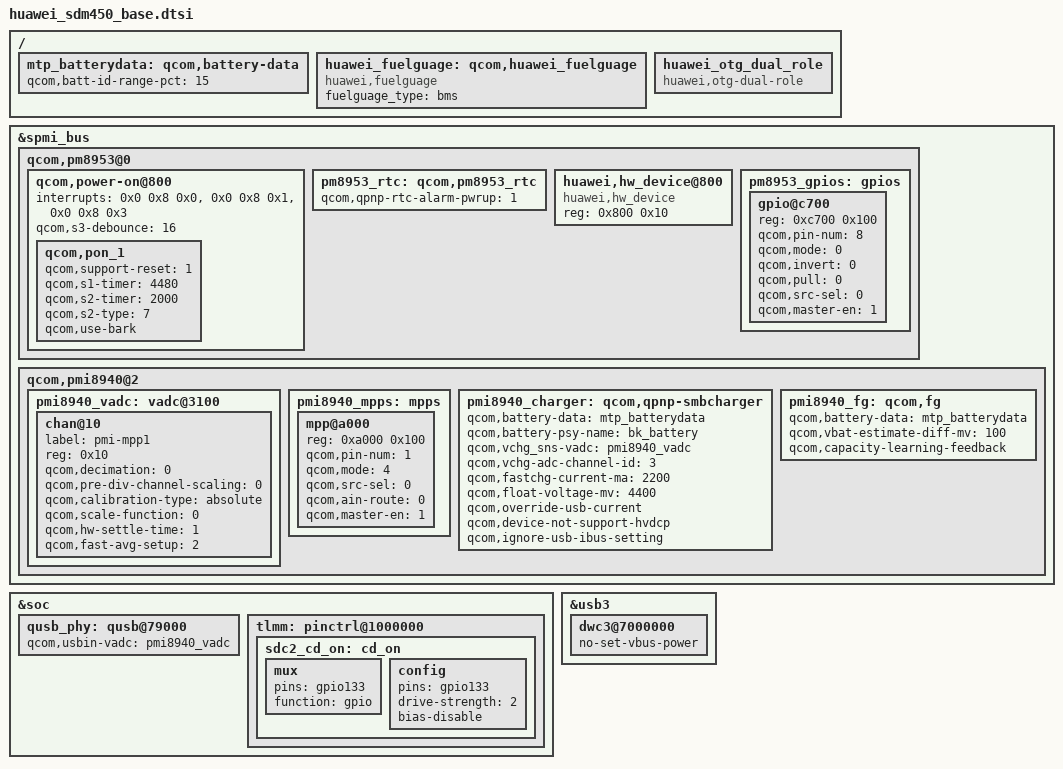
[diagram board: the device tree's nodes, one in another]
#include "sdm450.dtsi"
#include "msm-pmi8940.dtsi"
#include "msm8953-mtp.dtsi"
#include "msm8953-pmi8940.dtsi"
/*#include "msm8953-camera-sensor-mtp.dtsi"*/

&spmi_bus {
	qcom,pm8953@0 {
		qcom,power-on@800 {
			interrupts = <0x0 0x8 0x0>,
				<0x0 0x8 0x1>,
				<0x0 0x8 0x3>;
			interrupt-names = "kpdpwr", "resin","kpdpwr-bark";
			qcom,s3-debounce = <16>;
			qcom,pon_1 {
				qcom,support-reset = <1>;
				qcom,s1-timer = <4480>;
				qcom,s2-timer = <2000>;
				qcom,s2-type = <7>;
				qcom,use-bark;
			};
		};
		pm8953_rtc: qcom,pm8953_rtc {
			qcom,qpnp-rtc-alarm-pwrup = <1>;
		};
		huawei,hw_device@800 {
			compatible = "huawei,hw_device";
			reg = <0x800 0x10>;
		};
		pm8953_gpios: gpios {
			gpio@c700 {
			status = "ok";
			reg = <0xc700 0x100>;
			qcom,pin-num = <8>;
			qcom,mode = <0>;
			qcom,invert = <0>;
			qcom,pull = <0>;
			qcom,src-sel = <0>;
			qcom,master-en = <1>;
			};
		};
	};
	qcom,pmi8940@2 {
		pmi8940_vadc: vadc@3100 {
			chan@10 {
				label = "pmi-mpp1";
				reg = <0x10>; // channel for MPP1
				qcom,decimation = <0>;
				qcom,pre-div-channel-scaling = <0>; //Use 1:1 scaling to keep input voltage with in Max voltage: 1.8V
				qcom,calibration-type = "absolute";
				qcom,scale-function = <0>;
				qcom,hw-settle-time = <1>;
				qcom,fast-avg-setup = <2>;
			};
		};
		pmi8940_mpps: mpps {
			mpp@a000 {
				reg = <0xa000 0x100>;
				qcom,pin-num = <1>;
				status = "ok";
				qcom,mode = <4>; // A-input
				qcom,src-sel = <0>; //MPP Constant
				qcom,ain-route = <0>; // QPNP_PIN_AIN_AMUX_CH5 = 0 for MPP1
				qcom,master-en = <1>; //Enable MPP
			};
		};
		pmi8940_charger: qcom,qpnp-smbcharger {
            qcom,battery-data = <&mtp_batterydata>;
			qcom,battery-psy-name="bk_battery";
			qcom,vchg_sns-vadc = <&pmi8940_vadc>;
			qcom,vchg-adc-channel-id = <3>;
			qcom,fastchg-current-ma = <2200>;
			qcom,float-voltage-mv = <4400>;
			qcom,override-usb-current;
			qcom,device-not-support-hvdcp;
			qcom,ignore-usb-ibus-setting;
		};
		pmi8940_fg: qcom,fg {
            qcom,battery-data = <&mtp_batterydata>;
			qcom,vbat-estimate-diff-mv = <100>;
            qcom,capacity-learning-feedback;
		};
	};
};
/{
     mtp_batterydata: qcom,battery-data {
         qcom,batt-id-range-pct = <15>;
         #include "batterydata-itech-3000mah.dtsi"
         #include "batterydata-ascent-3450mAh.dtsi"
     };
};
/{
	huawei_fuelguage: qcom,huawei_fuelguage{
		compatible = "huawei,fuelguage";
		fuelguage_type = "bms";
		status = "okay";
	};
};
/ {
	huawei_otg_dual_role:huawei_otg_dual_role{
		compatible = "huawei,otg-dual-role";
		status = "okay";
	};
};
&soc {
		qusb_phy: qusb@79000  {
		qcom,usbin-vadc = <&pmi8940_vadc>;
	};

	tlmm: pinctrl@1000000 {
		sdc2_cd_on: cd_on {
			mux {
				pins = "gpio133";
				function = "gpio";
			};

			config {
				pins = "gpio133";
				drive-strength = <2>;
				bias-disable;
			};
		};
	};
};

&usb3 {
    dwc3@7000000 {
        no-set-vbus-power;
    };
};
